# STM32U585 register map
File version: 2.2
CPU: CM33 r0p1, little endian, MPU, FPU, 4 interrupt priority bits
Registers are 32-bit, read-write, reset 0x0 unless marked. A register's access mark holds for its fields unless they carry their own. Offsets are from the block's base; [hi:lo] are bit positions; {n}, {i} and the like mark numbered series.

## TAMP — Tamper and backup registers
Base 0x46007C00
Same registers: SEC_TAMP 0x56007C00
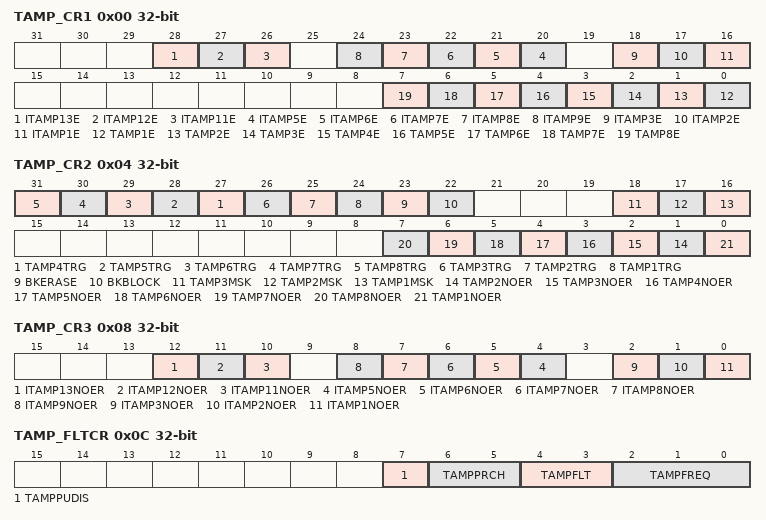
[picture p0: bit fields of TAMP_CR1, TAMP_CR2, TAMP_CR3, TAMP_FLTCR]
0x00 TAMP_CR1 — TAMP control register 1
  [28] ITAMP13E — Internal tamper 13 enable
    0=Internal tamper 13 disabled; 1=Internal tamper 13 enabled
  [27] ITAMP12E — Internal tamper 12 enable
    0=Internal tamper 12 disabled; 1=Internal tamper 12 enabled
  [26] ITAMP11E — Internal tamper 11 enable
    0=Internal tamper 11 disabled; 1=Internal tamper 11 enabled
  [n+15] ITAMP{n}E (n=5..9) — Internal tamper {n} enable
    0=Internal tamper {n} disabled; 1=Internal tamper {n} enabled
  [18] ITAMP3E — Internal tamper 3 enable
    0=Internal tamper 3 disabled; 1=Internal tamper 3 enabled
  [17] ITAMP2E — Internal tamper 2 enable
    0=Internal tamper 2 disabled; 1=Internal tamper 2 enabled
  [16] ITAMP1E — Internal tamper 1 enable
    0=Internal tamper 1 disabled; 1=Internal tamper 1 enabled
  [n-1] TAMP{n}E (n=1..8) — Tamper detection on TAMP_IN{n} enable
    0=Tamper detection on TAMP_IN{n} is disabled; 1=Tamper detection on TAMP_IN{n} is enabled
0x04 TAMP_CR2 access per field — TAMP control register 2
  [n+23] TAMP{n}TRG rw (n=4..8) — Active level for tamper {n} input (active mode disabled)
    0=If TAMPFLT 00 Tamper {n} input staying low triggers a tamper detection event; 1=If TAMPFLT 00 Tamper {n} input staying high triggers a tamper detection event
  [26] TAMP3TRG rw — Active level for tamper 3 input
    0=If TAMPFLT 00 Tamper 3 input staying low triggers a tamper detection event; 1=If TAMPFLT 00 Tamper 3 input staying high triggers a tamper detection event
  [25] TAMP2TRG rw — Active level for tamper 2 input
    0=If TAMPFLT 00 Tamper 2 input staying low triggers a tamper detection event; 1=If TAMPFLT 00 Tamper 2 input staying high triggers a tamper detection event
  [24] TAMP1TRG rw — Active level for tamper 1 input
    0=If TAMPFLT 00 Tamper 1 input staying low triggers a tamper detection event; 1=If TAMPFLT 00 Tamper 1 input staying high triggers a tamper detection event
  [23] BKERASE wo — Backup registers and device secrets erase
  [22] BKBLOCK rw — Backup registers and device secrets access blocked
    0=backup registers and device secrets(1) can be accessed if no tamper flag is set; 1=backup registers and device secrets(1) cannot be accessed
  [18] TAMP3MSK rw — Tamper 3 mask
    0=Tamper 3 event generates a trigger event and TAMP3F must be cleared by software to allow next tamper event detection; 1=Tamper 3 event generates a trigger event. TAMP3F is masked and internally cleared by hardware. The backup registers and device secrets are not erased.
  [17] TAMP2MSK rw — Tamper 2 mask
    0=Tamper 2 event generates a trigger event and TAMP2F must be cleared by software to allow next tamper event detection; 1=Tamper 2 event generates a trigger event. TAMP2F is masked and internally cleared by hardware. The backup registers and device secrets are not erased.
  [16] TAMP1MSK rw — Tamper 1 mask
    0=Tamper 1 event generates a trigger event and TAMP1F must be cleared by software to allow next tamper event detection; 1=Tamper 1 event generates a trigger event. TAMP1F is masked and internally cleared by hardware. The backup registers and device secrets are not erased.
  [n-1] TAMP{n}NOER rw (n=2..8) — Tamper {n} no erase
    0=Tamper {n} event erases the backup registers and all device secrets(1); 1=Tamper {n} event does not erase the backup registers and device secrets(2)
  [0] TAMP1NOER rw — Tamper 1 no erase
    0=Tamper 1 event erases the backup registers and all device secrets; 1=Tamper 1 event does not erase the backup registers and device secrets
0x08 TAMP_CR3 — TAMP control register 3
  [12] ITAMP13NOER — Internal Tamper 13 no erase
    0=Internal Tamper 13 event erases the backup registers and all device secrets(1); 1=Internal Tamper 13 event does not erase the backup registers and device secrets(2)
  [11] ITAMP12NOER — Internal Tamper 12 no erase
    0=Internal Tamper 12 event erases the backup registers and all device secrets(1); 1=Internal Tamper 12 event does not erase the backup registers and device secrets(2)
  [10] ITAMP11NOER — Internal Tamper 11 no erase
    0=Internal Tamper 11 event erases the backup registers and all device secrets(1); 1=Internal Tamper 11 event does not erase the backup registers and device secrets(2)
  [n-1] ITAMP{n}NOER (n=5..9) — Internal Tamper {n} no erase
    0=Internal Tamper {n} event erases the backup registers and all device secrets(1); 1=Internal Tamper {n} event does not erase the backup registers and device secrets(2)
  [2] ITAMP3NOER — Internal Tamper 3 no erase
    0=Internal Tamper 3 event erases the backup registers and all device secrets(1); 1=Internal Tamper 3 event does not erase the backup registers and device secrets(2)
  [1] ITAMP2NOER — Internal Tamper 2 no erase
    0=Internal Tamper 2 event erases the backup registers and all device secrets(1); 1=Internal Tamper 2 event does not erase the backup registers and device secrets(2)
  [0] ITAMP1NOER — Internal Tamper 1 no erase
    0=Internal Tamper 1 event erases the backup registers and all device secrets; 1=Internal Tamper 1 event does not erase the backup registers and device secrets
0x0C TAMP_FLTCR — TAMP filter control register
  [7] TAMPPUDIS — TAMP_INx pull-up disable
    0=Precharge TAMP_INx pins before sampling (enable internal pull-up); 1=Disable precharge of TAMP_INx pins
  [6:5] TAMPPRCH — TAMP_INx precharge duration
    0=1 RTCCLK cycle; 1=2 RTCCLK cycles; 2=4 RTCCLK cycles; 3=8 RTCCLK cycles
  [4:3] TAMPFLT — TAMP_INx filter count
    0=Tamper event is activated on edge of TAMP_INx input transitions to the active level (no internal pull-up on TAMP_INx input); 1=Tamper event is activated after 2 consecutive samples at the active level; 2=Tamper event is activated after 4 consecutive samples at the active level; 3=Tamper event is activated after 8 consecutive samples at the active level
  [2:0] TAMPFREQ — Tamper sampling frequency
    0=RTCCLK / 32768 (1 Hz when RTCCLK = 32768 Hz); 1=RTCCLK / 16384 (2 Hz when RTCCLK = 32768 Hz); 2=RTCCLK / 8192 (4 Hz when RTCCLK = 32768 Hz); 3=RTCCLK / 4096 (8 Hz when RTCCLK = 32768 Hz); 4=RTCCLK / 2048 (16 Hz when RTCCLK = 32768 Hz); 5=RTCCLK / 1024 (32 Hz when RTCCLK = 32768 Hz); 6=RTCCLK / 512 (64 Hz when RTCCLK = 32768 Hz); 7=RTCCLK / 256 (128 Hz when RTCCLK = 32768 Hz)
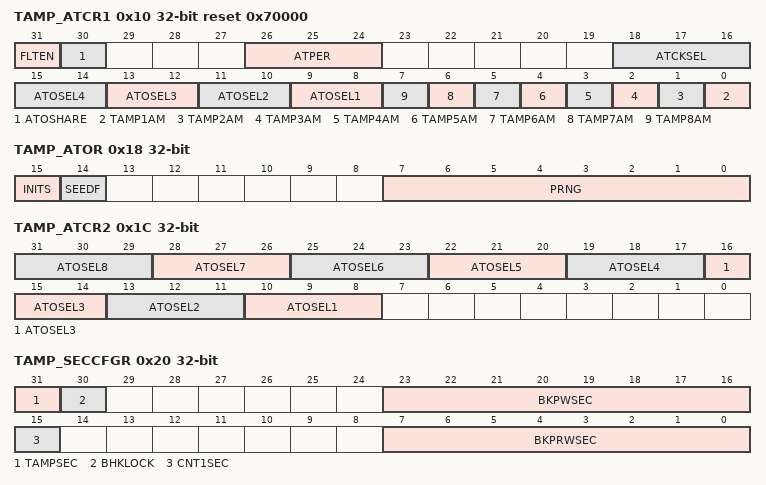
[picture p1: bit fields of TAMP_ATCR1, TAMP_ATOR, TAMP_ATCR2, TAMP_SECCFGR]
0x10 TAMP_ATCR1 reset 0x70000 — TAMP active tamper control register 1
  [31] FLTEN — Active tamper filter enable
    0=Active tamper filtering disable; 1=Active tamper filtering enable: a tamper event is detected when 2 comparison mismatches occur out of 4 consecutive samples
  [30] ATOSHARE — Active tamper output sharing
    0=Each active tamper input TAMP_INi is compared with its dedicated output TAMP_OUTi; 1=Each active tamper input TAMP_INi is compared with TAMPOUTSELx as defined below, with TAMPOUTSELx defined by ATOSELx bits
  [26:24] ATPER — Active tamper output change period
  [18:16] ATCKSEL — Active tamper RTC asynchronous prescaler clock selection
    0=RTCCLK is selected; 1=RTCCLK/2 is selected when (PREDIV_A+1) = 128 (actually selects 1st flip flop output); 2=RTCCLK/4 is selected when (PREDIV_A+1) = 128 (actually selects 2nd flip flop output); 7=RTCCLK/128 is selected when (PREDIV_A+1) = 128 (actually selects 7th flip flop output)
  [2n+7:2n+6] ATOSEL{n} (n=1..4) — Active tamper shared output {n} selection
    {v}=TAMPOUTSEL{n} = TAMP_OUT{v+1} (v=0..3)
  [n-1] TAMP{n}AM (n=1..8) — Tamper {n} active mode
    0=Tamper {n} detection mode is passive; 1=Tamper {n} detection mode is active
0x14 TAMP_ATSEEDR wo — TAMP active tamper seed register
  [31:0] SEED — Pseudo-random generator seed value
0x18 TAMP_ATOR ro — TAMP active tamper output register
  [15] INITS — Active tamper initialization status
  [14] SEEDF — Seed running flag
  [7:0] PRNG — Pseudo-random generator value
0x1C TAMP_ATCR2 — TAMP active tamper control register 2
  [3n+7:3n+5] ATOSEL{n} (n=1..8) — Active tamper shared output {n} selection
    {v}=TAMPOUTSEL{n} = TAMP_OUT{v+1} (v=0..7)
0x20 TAMP_SECCFGR — TAMP secure mode register
  [31] TAMPSEC — Tamper protection (excluding monotonic counters and backup registers)
    0=Tamper configuration and interrupt can be written when the APB access is secure or non-secure; 1=Tamper configuration and interrupt can be written only when the APB access is secure
  [30] BHKLOCK — Boot hardware key lock
    0=The Backup registers from TAMP_BKP0R to TAMP_BKP7R can be accessed according to the Protection zone they belong to; 1=The backup registers from TAMP_BKP0R to TAMP_BKP7R cannot be accessed neither in read nor in write (they are read as 0 and write ignore)
  [23:16] BKPWSEC — Backup registers write protection offset
  [15] CNT1SEC — Monotonic counter 1 secure protection
    0=Monotonic counter 1 (TAMP_COUNT1R) can be read and written when the APB access is secure or non-secure; 1=Monotonic counter 1 (TAMP_COUNT1R) can be read and written only when the APB access is secure
  [7:0] BKPRWSEC — Backup registers read/write protection offset
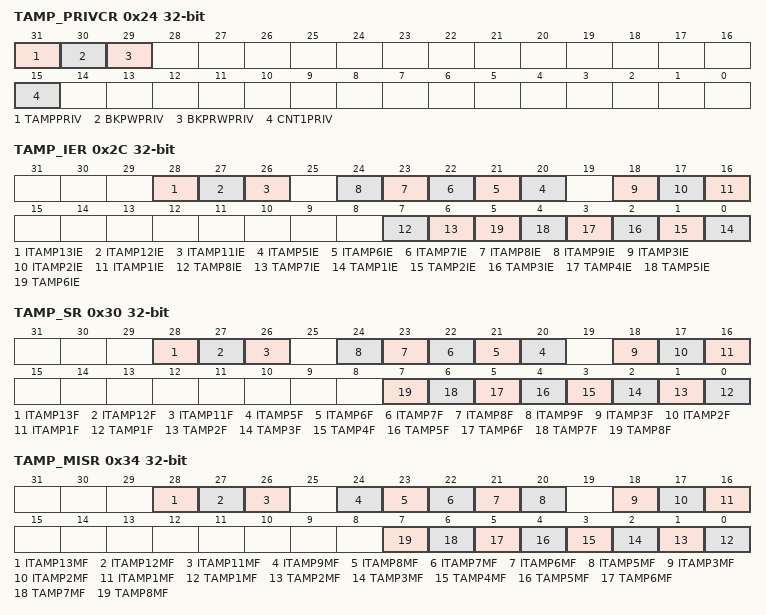
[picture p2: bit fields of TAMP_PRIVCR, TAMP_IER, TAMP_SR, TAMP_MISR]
0x24 TAMP_PRIVCR — TAMP privilege mode control register
  [31] TAMPPRIV — Tamper privilege protection (excluding backup registers)
    0=Tamper configuration and interrupt can be written with privileged or unprivileged access; 1=Tamper configuration and interrupt can be written only with privileged access
  [30] BKPWPRIV — Backup registers zone 2 privilege protection
    0=Backup registers zone 2 can be written with privileged or unprivileged access; 1=Backup registers zone 2 can be written only with privileged access
  [29] BKPRWPRIV — Backup registers zone 1 privilege protection
    0=Backup registers zone 1 can be read and written with privileged or unprivileged access; 1=Backup registers zone 1 can be read and written only with privileged access
  [15] CNT1PRIV — Monotonic counter 1 privilege protection
    0=Monotonic counter 1 (TAMP_COUNT1R) can be read and written when the APB access is privileged or non-privileged; 1=Monotonic counter 1 (TAMP_COUNT1R) can be read and written only when the APB access is privileged
0x2C TAMP_IER — TAMP interrupt enable register
  [28] ITAMP13IE — Internal tamper 13 interrupt enable
    0=Internal tamper 13 interrupt disabled; 1=Internal tamper 13 interrupt enabled
  [27] ITAMP12IE — Internal tamper 12 interrupt enable
    0=Internal tamper 12 interrupt disabled; 1=Internal tamper 12 interrupt enabled
  [26] ITAMP11IE — Internal tamper 11 interrupt enable
    0=Internal tamper 11 interrupt disabled; 1=Internal tamper 11 interrupt enabled
  [n+15] ITAMP{n}IE (n=5..9) — Internal tamper {n} interrupt enable
    0=Internal tamper {n} interrupt disabled; 1=Internal tamper {n} interrupt enabled
  [18] ITAMP3IE — Internal tamper 3 interrupt enable
    0=Internal tamper 3 interrupt disabled; 1=Internal tamper 3 interrupt enabled
  [17] ITAMP2IE — Internal tamper 2 interrupt enable
    0=Internal tamper 2 interrupt disabled; 1=Internal tamper 2 interrupt enabled
  [16] ITAMP1IE — Internal tamper 1 interrupt enable
    0=Internal tamper 1 interrupt disabled; 1=Internal tamper 1 interrupt enabled
  [7] TAMP8IE — Tamper 8 interrupt enable
    0=Tamper 8 interrupt disabled; 1=Tamper 8 interrupt enabled
  [6] TAMP7IE — Tamper 7interrupt enable
    0=Tamper 7 interrupt disabled; 1=Tamper 7interrupt enabled
  [n-1] TAMP{n}IE (n=1..6) — Tamper {n} interrupt enable
    0=Tamper {n} interrupt disabled; 1=Tamper {n} interrupt enabled
0x30 TAMP_SR ro — TAMP status register
  [28] ITAMP13F — Internal tamper 13 flag
  [27] ITAMP12F — Internal tamper 12 flag
  [26] ITAMP11F — Internal tamper 11 flag
  [n+15] ITAMP{n}F (n=5..9) — Internal tamper {n} flag
  [18] ITAMP3F — Internal tamper 3 flag
  [17] ITAMP2F — Internal tamper 2 flag
  [16] ITAMP1F — Internal tamper 1 flag
  [n-1] TAMP{n}F (n=1..8) — TAMP{n} detection flag
0x34 TAMP_MISR ro — TAMP non-secure masked interrupt status register
  [28] ITAMP13MF — internal tamper 13 non-secure interrupt masked flag
  [27] ITAMP12MF — internal tamper 12 non-secure interrupt masked flag
  [26] ITAMP11MF — internal tamper 11 non-secure interrupt masked flag
  [24] ITAMP9MF — internal tamper 9 non-secure interrupt masked flag
  [23] ITAMP8MF — Internal tamper 8 non-secure interrupt masked flag
  [22] ITAMP7MF — VCORE monitoring tamper non-secure interrupt masked flag
  [21] ITAMP6MF — Internal tamper 6 non-secure interrupt masked flag
  [20] ITAMP5MF — Internal tamper 5 non-secure interrupt masked flag
  [18] ITAMP3MF — Internal tamper 3 non-secure interrupt masked flag
  [17] ITAMP2MF — Internal tamper 2 non-secure interrupt masked flag
  [16] ITAMP1MF — Internal tamper 1 non-secure interrupt masked flag
  [n-1] TAMP{n}MF (n=1..8) — TAMP{n} non-secure interrupt masked flag
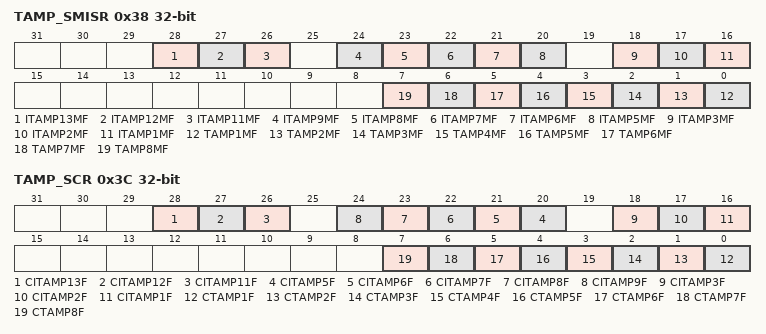
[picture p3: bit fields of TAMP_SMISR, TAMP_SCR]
0x38 TAMP_SMISR ro — TAMP secure masked interrupt status register
  [28] ITAMP13MF — internal tamper 13 secure interrupt masked flag
  [27] ITAMP12MF — internal tamper 12 secure interrupt masked flag
  [26] ITAMP11MF — internal tamper 11 secure interrupt masked flag
  [24] ITAMP9MF — internal tamper 9 secure interrupt masked flag
  [23] ITAMP8MF — Internal tamper 8 secure interrupt masked flag
  [22] ITAMP7MF — VCORE monitoring tamper secure interrupt masked flag
  [21] ITAMP6MF — Internal tamper 6 secure interrupt masked flag
  [20] ITAMP5MF — Internal tamper 5 secure interrupt masked flag
  [18] ITAMP3MF — Internal tamper 3 secure interrupt masked flag
  [17] ITAMP2MF — Internal tamper 2 secure interrupt masked flag
  [16] ITAMP1MF — Internal tamper 1 secure interrupt masked flag
  [n-1] TAMP{n}MF (n=1..8) — TAMP{n} secure interrupt masked flag
0x3C TAMP_SCR wo — TAMP status clear register
  [28] CITAMP13F — Clear ITAMP13 detection flag
  [27] CITAMP12F — Clear ITAMP12 detection flag
  [26] CITAMP11F — Clear ITAMP11 detection flag
  [n+15] CITAMP{n}F (n=5..9) — Clear ITAMP{n} detection flag
  [18] CITAMP3F — Clear ITAMP3 detection flag
  [17] CITAMP2F — Clear ITAMP2 detection flag
  [16] CITAMP1F — Clear ITAMP1 detection flag
  [n-1] CTAMP{n}F (n=1..8) — Clear TAMP{n} detection flag
0x40 TAMP_COUNT1R ro — TAMP monotonic counter 1 register
  [31:0] COUNT — This register is read-only only and is incremented by one when a write access is done to this register. This register cannot roll-over and is frozen when reaching the maximum value.
0x54 TAMP_ERCFGR — TAMP erase configuration register
  [0] ERCFG0 — Configurable device secrets configuration
    0=Configurable device secrets are not included in the device secrets protected by TAMP peripheral; 1=Configurable device secrets are is included in the device secrets protected by TAMP peripheral
{0x100+4i} TAMP_BKP{i}R (i=0..31) — TAMP backup {i} register
  [31:0] BKP — The application can write or read data to and from these registers.
